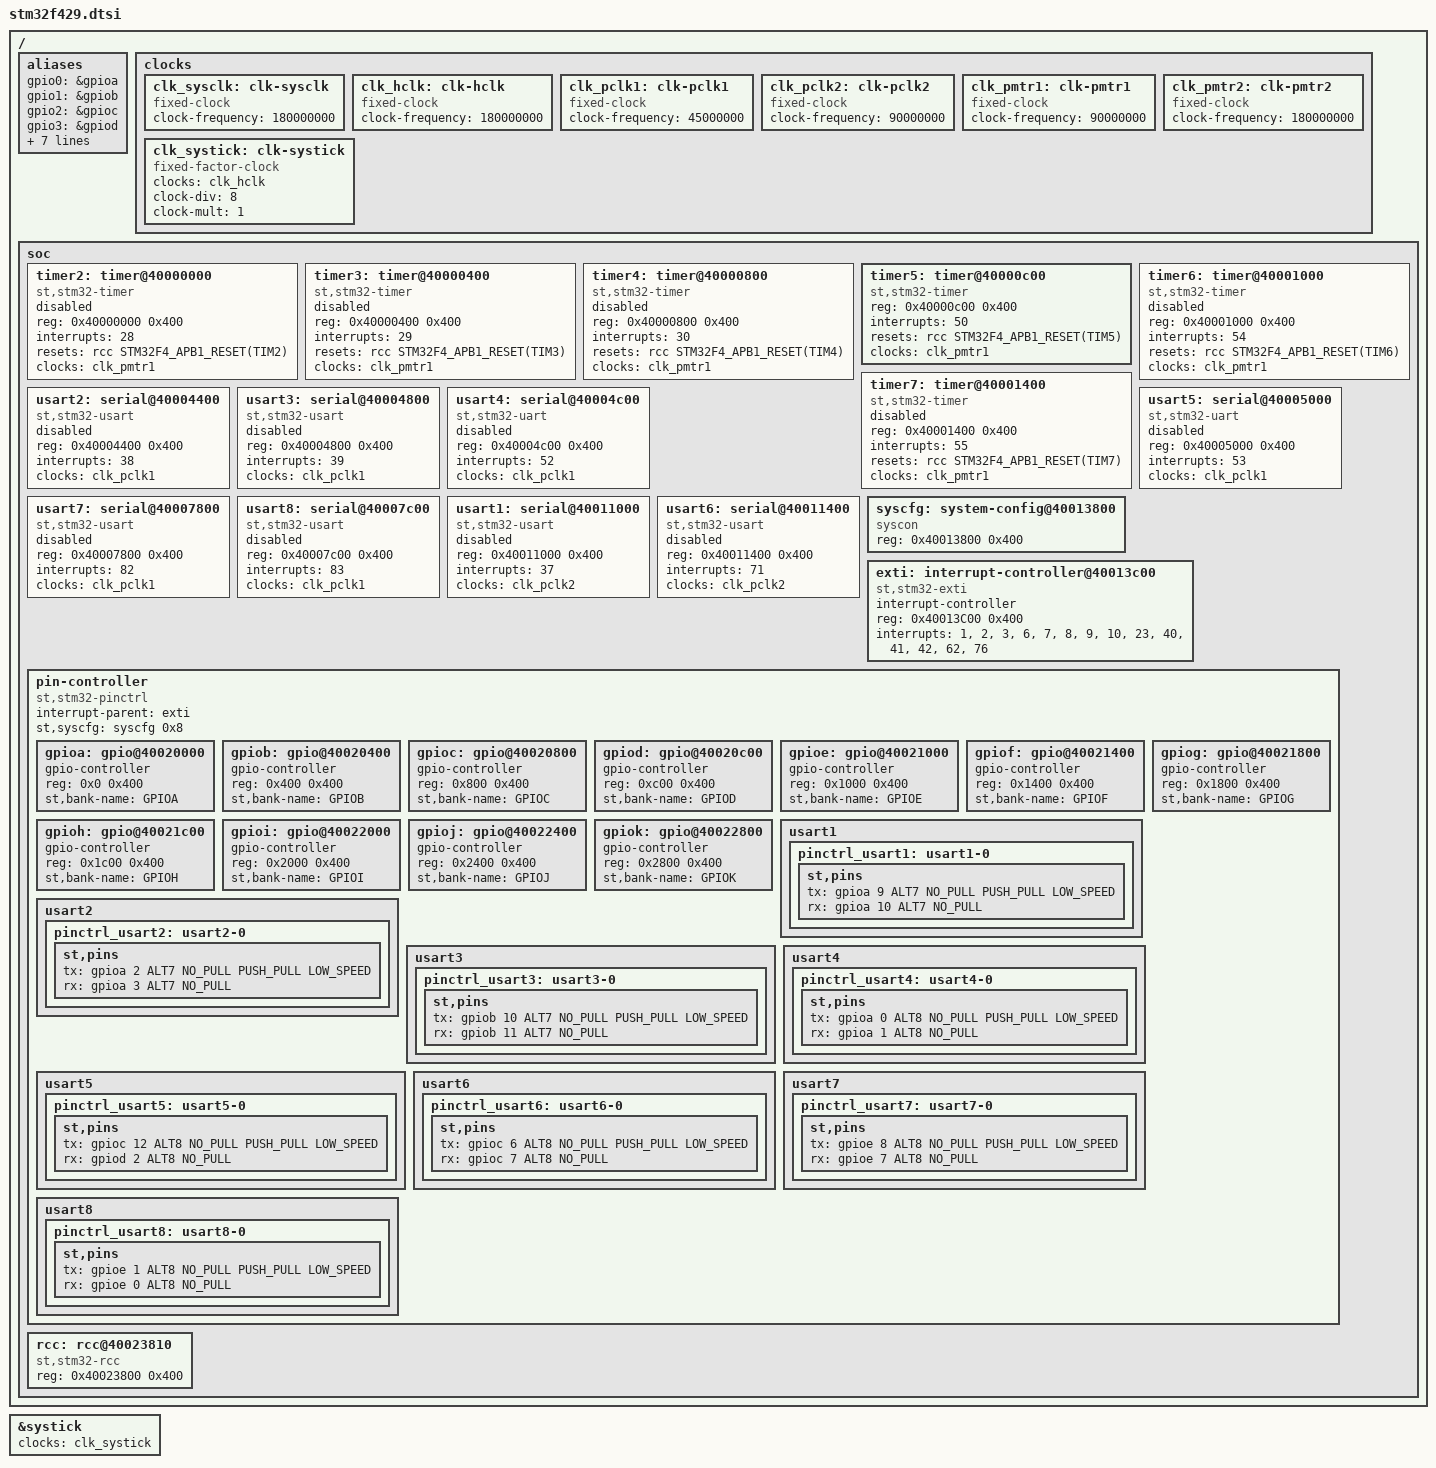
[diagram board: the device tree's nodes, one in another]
/*
 * Copyright 2015 - Maxime Coquelin <mcoquelin.stm32@gmail.com>
 *
 * This file is dual-licensed: you can use it either under the terms
 * of the GPL or the X11 license, at your option. Note that this dual
 * licensing only applies to this file, and not this project as a
 * whole.
 *
 *  a) This file is free software; you can redistribute it and/or
 *     modify it under the terms of the GNU General Public License as
 *     published by the Free Software Foundation; either version 2 of the
 *     License, or (at your option) any later version.
 *
 *     This file is distributed in the hope that it will be useful,
 *     but WITHOUT ANY WARRANTY; without even the implied warranty of
 *     MERCHANTABILITY or FITNESS FOR A PARTICULAR PURPOSE.  See the
 *     GNU General Public License for more details.
 *
 *     You should have received a copy of the GNU General Public
 *     License along with this file; if not, write to the Free
 *     Software Foundation, Inc., 51 Franklin St, Fifth Floor, Boston,
 *     MA 02110-1301 USA
 *
 * Or, alternatively,
 *
 *  b) Permission is hereby granted, free of charge, to any person
 *     obtaining a copy of this software and associated documentation
 *     files (the "Software"), to deal in the Software without
 *     restriction, including without limitation the rights to use,
 *     copy, modify, merge, publish, distribute, sublicense, and/or
 *     sell copies of the Software, and to permit persons to whom the
 *     Software is furnished to do so, subject to the following
 *     conditions:
 *
 *     The above copyright notice and this permission notice shall be
 *     included in all copies or substantial portions of the Software.
 *
 *     THE SOFTWARE IS PROVIDED "AS IS", WITHOUT WARRANTY OF ANY KIND,
 *     EXPRESS OR IMPLIED, INCLUDING BUT NOT LIMITED TO THE WARRANTIES
 *     OF MERCHANTABILITY, FITNESS FOR A PARTICULAR PURPOSE AND
 *     NONINFRINGEMENT. IN NO EVENT SHALL THE AUTHORS OR COPYRIGHT
 *     HOLDERS BE LIABLE FOR ANY CLAIM, DAMAGES OR OTHER LIABILITY,
 *     WHETHER IN AN ACTION OF CONTRACT, TORT OR OTHERWISE, ARISING
 *     FROM, OUT OF OR IN CONNECTION WITH THE SOFTWARE OR THE USE OR
 *     OTHER DEALINGS IN THE SOFTWARE.
 */

#include <dt-bindings/pinctrl/pinctrl-stm32.h>
#include "armv7-m.dtsi"
#include  <dt-bindings/mfd/stm32f4-rcc.h>

/ {

	aliases {
		gpio0 = &gpioa;
		gpio1 = &gpiob;
		gpio2 = &gpioc;
		gpio3 = &gpiod;
		gpio4 = &gpioe;
		gpio5 = &gpiof;
		gpio6 = &gpiog;
		gpio7 = &gpioh;
		gpio8 = &gpioi;
		gpio9 = &gpioj;
		gpio10 = &gpiok;
	};

	clocks {
		clk_sysclk: clk-sysclk {
			#clock-cells = <0>;
			compatible = "fixed-clock";
			clock-frequency = <180000000>;
		};

		clk_hclk: clk-hclk {
			#clock-cells = <0>;
			compatible = "fixed-clock";
			clock-frequency = <180000000>;
		};

		clk_pclk1: clk-pclk1 {
			#clock-cells = <0>;
			compatible = "fixed-clock";
			clock-frequency = <45000000>;
		};

		clk_pclk2: clk-pclk2 {
			#clock-cells = <0>;
			compatible = "fixed-clock";
			clock-frequency = <90000000>;
		};

		clk_pmtr1: clk-pmtr1 {
			#clock-cells = <0>;
			compatible = "fixed-clock";
			clock-frequency = <90000000>;
		};

		clk_pmtr2: clk-pmtr2 {
			#clock-cells = <0>;
			compatible = "fixed-clock";
			clock-frequency = <180000000>;
		};

		clk_systick: clk-systick {
			compatible = "fixed-factor-clock";
			clocks = <&clk_hclk>;
			#clock-cells = <0>;
			clock-div = <8>;
			clock-mult = <1>;
		};
	};

	soc {
		timer2: timer@40000000 {
			compatible = "st,stm32-timer";
			reg = <0x40000000 0x400>;
			interrupts = <28>;
			resets = <&rcc STM32F4_APB1_RESET(TIM2)>;
			clocks = <&clk_pmtr1>;
			status = "disabled";
		};

		timer3: timer@40000400 {
			compatible = "st,stm32-timer";
			reg = <0x40000400 0x400>;
			interrupts = <29>;
			resets = <&rcc STM32F4_APB1_RESET(TIM3)>;
			clocks = <&clk_pmtr1>;
			status = "disabled";
		};

		timer4: timer@40000800 {
			compatible = "st,stm32-timer";
			reg = <0x40000800 0x400>;
			interrupts = <30>;
			resets = <&rcc STM32F4_APB1_RESET(TIM4)>;
			clocks = <&clk_pmtr1>;
			status = "disabled";
		};

		timer5: timer@40000c00 {
			compatible = "st,stm32-timer";
			reg = <0x40000c00 0x400>;
			interrupts = <50>;
			resets = <&rcc STM32F4_APB1_RESET(TIM5)>;
			clocks = <&clk_pmtr1>;
		};

		timer6: timer@40001000 {
			compatible = "st,stm32-timer";
			reg = <0x40001000 0x400>;
			interrupts = <54>;
			resets = <&rcc STM32F4_APB1_RESET(TIM6)>;
			clocks = <&clk_pmtr1>;
			status = "disabled";
		};

		timer7: timer@40001400 {
			compatible = "st,stm32-timer";
			reg = <0x40001400 0x400>;
			interrupts = <55>;
			resets = <&rcc STM32F4_APB1_RESET(TIM7)>;
			clocks = <&clk_pmtr1>;
			status = "disabled";
		};

		usart2: serial@40004400 {
			compatible = "st,stm32-usart", "st,stm32-uart";
			reg = <0x40004400 0x400>;
			interrupts = <38>;
			clocks = <&clk_pclk1>;
			status = "disabled";
		};

		usart3: serial@40004800 {
			compatible = "st,stm32-usart", "st,stm32-uart";
			reg = <0x40004800 0x400>;
			interrupts = <39>;
			clocks = <&clk_pclk1>;
			status = "disabled";
		};

		usart4: serial@40004c00 {
			compatible = "st,stm32-uart";
			reg = <0x40004c00 0x400>;
			interrupts = <52>;
			clocks = <&clk_pclk1>;
			status = "disabled";
		};

		usart5: serial@40005000 {
			compatible = "st,stm32-uart";
			reg = <0x40005000 0x400>;
			interrupts = <53>;
			clocks = <&clk_pclk1>;
			status = "disabled";
		};

		usart7: serial@40007800 {
			compatible = "st,stm32-usart", "st,stm32-uart";
			reg = <0x40007800 0x400>;
			interrupts = <82>;
			clocks = <&clk_pclk1>;
			status = "disabled";
		};

		usart8: serial@40007c00 {
			compatible = "st,stm32-usart", "st,stm32-uart";
			reg = <0x40007c00 0x400>;
			interrupts = <83>;
			clocks = <&clk_pclk1>;
			status = "disabled";
		};

		usart1: serial@40011000 {
			compatible = "st,stm32-usart", "st,stm32-uart";
			reg = <0x40011000 0x400>;
			interrupts = <37>;
			clocks = <&clk_pclk2>;
			status = "disabled";
		};

		usart6: serial@40011400 {
			compatible = "st,stm32-usart", "st,stm32-uart";
			reg = <0x40011400 0x400>;
			interrupts = <71>;
			clocks = <&clk_pclk2>;
			status = "disabled";
		};

		syscfg: system-config@40013800 {
			compatible = "syscon";
			reg = <0x40013800 0x400>;
		};

		exti: interrupt-controller@40013c00 {
			compatible = "st,stm32-exti";
			interrupt-controller;
			#interrupt-cells = <2>;
			reg = <0x40013C00 0x400>;
			interrupts = <1>, <2>, <3>, <6>, <7>, <8>, <9>, <10>, <23>, <40>, <41>, <42>, <62>, <76>; 
		};

		pin-controller {
			#address-cells = <1>;
			#size-cells = <1>;
			compatible = "st,stm32-pinctrl";
			ranges = <0 0x40020000 0x3000>;
			interrupt-parent = <&exti>;
			st,syscfg = <&syscfg 0x8>;

			gpioa: gpio@40020000 {
				gpio-controller;
				#gpio-cells = <2>;
				reg = <0x0 0x400>;
				st,bank-name = "GPIOA";
			};

			gpiob: gpio@40020400 {
				gpio-controller;
				#gpio-cells = <2>;
				reg = <0x400 0x400>;
				st,bank-name = "GPIOB";
			};

			gpioc: gpio@40020800 {
				gpio-controller;
				#gpio-cells = <2>;
				reg = <0x800 0x400>;
				st,bank-name = "GPIOC";
			};

			gpiod: gpio@40020c00 {
				gpio-controller;
				#gpio-cells = <2>;
				reg = <0xc00 0x400>;
				st,bank-name = "GPIOD";
			};

			gpioe: gpio@40021000 {
				gpio-controller;
				#gpio-cells = <2>;
				reg = <0x1000 0x400>;
				st,bank-name = "GPIOE";
			};

			gpiof: gpio@40021400 {
				gpio-controller;
				#gpio-cells = <2>;
				reg = <0x1400 0x400>;
				st,bank-name = "GPIOF";
			};

			gpiog: gpio@40021800 {
				gpio-controller;
				#gpio-cells = <2>;
				reg = <0x1800 0x400>;
				st,bank-name = "GPIOG";
			};

			gpioh: gpio@40021c00 {
				gpio-controller;
				#gpio-cells = <2>;
				reg = <0x1c00 0x400>;
				st,bank-name = "GPIOH";
			};

			gpioi: gpio@40022000 {
				gpio-controller;
				#gpio-cells = <2>;
				reg = <0x2000 0x400>;
				st,bank-name = "GPIOI";
			};

			gpioj: gpio@40022400 {
				gpio-controller;
				#gpio-cells = <2>;
				reg = <0x2400 0x400>;
				st,bank-name = "GPIOJ";
			};

			gpiok: gpio@40022800 {
				gpio-controller;
				#gpio-cells = <2>;
				reg = <0x2800 0x400>;
				st,bank-name = "GPIOK";
			};

			usart1 {
				pinctrl_usart1: usart1-0 {
					st,pins {
						tx = <&gpioa 9 ALT7 NO_PULL PUSH_PULL LOW_SPEED>;
						rx = <&gpioa 10 ALT7 NO_PULL>;
					};
				};
			};

			usart2 {
				pinctrl_usart2: usart2-0 {
					st,pins {
						tx = <&gpioa 2 ALT7 NO_PULL PUSH_PULL LOW_SPEED>;
						rx = <&gpioa 3 ALT7 NO_PULL>;
					};
				};
			};

			usart3 {
				pinctrl_usart3: usart3-0 {
					st,pins {
						tx = <&gpiob 10 ALT7 NO_PULL PUSH_PULL LOW_SPEED>;
						rx = <&gpiob 11 ALT7 NO_PULL>;
					};
				};
			};

			usart4 {
				pinctrl_usart4: usart4-0 {
					st,pins {
						tx = <&gpioa 0 ALT8 NO_PULL PUSH_PULL LOW_SPEED>;
						rx = <&gpioa 1 ALT8 NO_PULL>;
					};
				};
			};

			usart5 {
				pinctrl_usart5: usart5-0 {
					st,pins {
						tx = <&gpioc 12 ALT8 NO_PULL PUSH_PULL LOW_SPEED>;
						rx = <&gpiod 2 ALT8 NO_PULL>;
					};
				};
			};

			usart6 {
				pinctrl_usart6: usart6-0 {
					st,pins {
						tx = <&gpioc 6 ALT8 NO_PULL PUSH_PULL LOW_SPEED>;
						rx = <&gpioc 7 ALT8 NO_PULL>;
					};
				};
			};

			usart7 {
				pinctrl_usart7: usart7-0 {
					st,pins {
						tx = <&gpioe 8 ALT8 NO_PULL PUSH_PULL LOW_SPEED>;
						rx = <&gpioe 7 ALT8 NO_PULL>;
					};
				};
			};

			usart8 {
				pinctrl_usart8: usart8-0 {
					st,pins {
						tx = <&gpioe 1 ALT8 NO_PULL PUSH_PULL LOW_SPEED>;
						rx = <&gpioe 0 ALT8 NO_PULL>;
					};
				};
			};
		};

		rcc: rcc@40023810 {
			#reset-cells = <1>;
			compatible = "st,stm32-rcc";
			reg = <0x40023800 0x400>;
		};
	};
};

&systick {
	clocks = <&clk_systick>;
	status = "okay";
};
